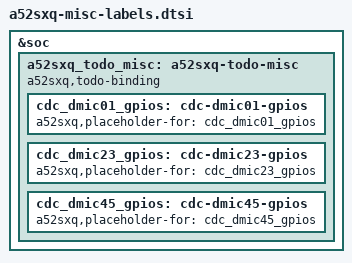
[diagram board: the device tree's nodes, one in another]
// SPDX-License-Identifier: GPL-2.0
/*
 * a52sxq board description for the Qualcomm 6.12 yupik base: placeholder labels for 'misc'
 * GENERATED by tools/gen.py from the phone's stock dtbo (5.4 bindings, values verbatim).
 * Do not edit: hand-written 6.12 changes live in a52sxq-bsp612-fixups.dtsi.
 */

/*
 * Labels of the 5.4 base that the 6.12 base does not have. Placeholders under
 * /soc/a52sxq-todo-misc (no compatible: nothing binds, children are not populated)
 * so that every reference of the phone's tree resolves. TODO-binding: replace by the
 * real 6.12 node of the owning driver and delete the placeholder.
 */
&soc {
	a52sxq_todo_misc: a52sxq-todo-misc {
		a52sxq,todo-binding;
		cdc_dmic01_gpios: cdc-dmic01-gpios {
			a52sxq,placeholder-for = "cdc_dmic01_gpios";
		};
		cdc_dmic23_gpios: cdc-dmic23-gpios {
			a52sxq,placeholder-for = "cdc_dmic23_gpios";
		};
		cdc_dmic45_gpios: cdc-dmic45-gpios {
			a52sxq,placeholder-for = "cdc_dmic45_gpios";
		};
	};
};

